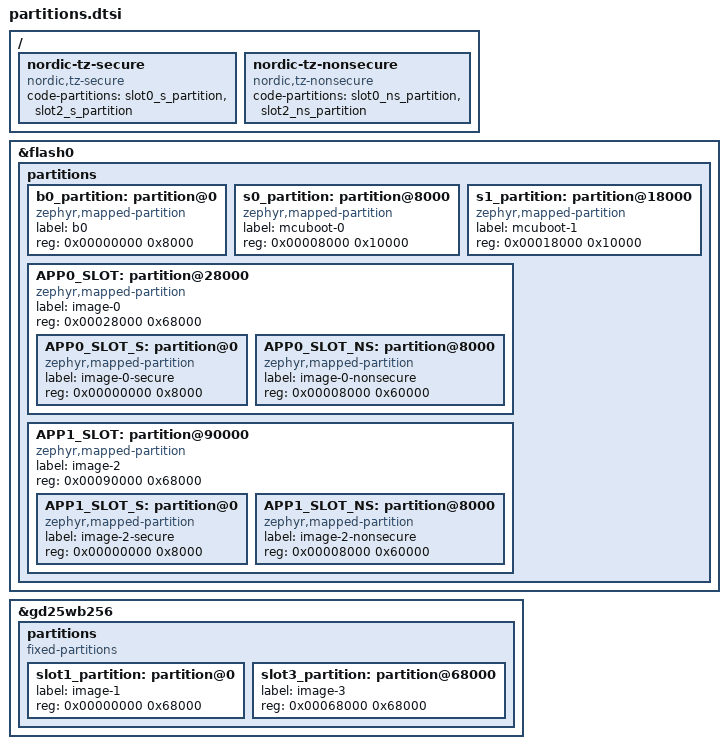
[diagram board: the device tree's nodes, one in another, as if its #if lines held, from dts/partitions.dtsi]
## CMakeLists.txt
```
cmake_minimum_required(VERSION 3.20.0)

find_package(Zephyr REQUIRED HINTS $ENV{ZEPHYR_BASE})
project(app0)

target_include_directories(app PRIVATE common)
target_sources(app PRIVATE src/main.c common/update.c)
```

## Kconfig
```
rsource "common/Kconfig"
source "Kconfig.zephyr"
```

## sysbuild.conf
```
# Two stage bootloader (b0 + MCUboot)
SB_CONFIG_SECURE_BOOT_APPCORE=y
SB_CONFIG_BOOTLOADER_MCUBOOT=y

SB_CONFIG_MCUBOOT_MODE_SWAP_USING_MOVE=y

# app0 = image 0, app1 = image 1
# MCUboot adds its own s0/s1 pair as image 2
SB_CONFIG_MCUBOOT_UPDATEABLE_IMAGES=2
```

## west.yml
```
manifest:
  remotes:
    - name: savosaicic
      url-base: https://github.com/savosaicic

  projects:
    - name: nrf
      repo-path: sdk-nrf
      remote: savosaicic
      revision: c24ab47cc679d7ebbf858c0a5f1238c8fe9de8c6
      import: true

  self:
    path: nrf-two-app
```

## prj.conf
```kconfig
CONFIG_LOG=y
CONFIG_REBOOT=y
CONFIG_DK_LIBRARY=y
CONFIG_TFM_PROFILE_TYPE_MINIMAL=y

CONFIG_MAIN_STACK_SIZE=4096
CONFIG_HEAP_MEM_POOL_SIZE=4096

# LTE
CONFIG_NRF_MODEM_LIB=y
CONFIG_LTE_LINK_CONTROL=y
CONFIG_NETWORKING=y
CONFIG_NET_SOCKETS=y
CONFIG_NET_NATIVE=n

# FOTA
CONFIG_FOTA_DOWNLOAD=y
CONFIG_DOWNLOADER=y
CONFIG_DOWNLOADER_STACK_SIZE=4096
CONFIG_DFU_TARGET=y
CONFIG_DFU_TARGET_MCUBOOT=y
CONFIG_IMG_MANAGER=y
CONFIG_STREAM_FLASH=y
CONFIG_IMG_ERASE_PROGRESSIVELY=y
CONFIG_FLASH=y
CONFIG_FLASH_MAP=y

# Secondary slots on external flash
CONFIG_SPI=y
CONFIG_SPI_NOR=y
CONFIG_SPI_NOR_SFDP_DEVICETREE=y
CONFIG_SPI_NOR_FLASH_LAYOUT_PAGE_SIZE=4096
```

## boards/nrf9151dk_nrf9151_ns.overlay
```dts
#include "../dts/partitions.dtsi"
#include <samples/cellular/nrf91_sram_partitions.dtsi>
```

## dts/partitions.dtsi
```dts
/*
 * Two application flash layout for the nRF9151DK
 *
 * MCUboot image pair 0 = app0 (primary slot0, secondary slot1)
 * MCUboot image pair 1 = app1 (primary slot2, secondary slot3)
 * MCUboot image pair 2 = MCUboot s0/s1 self-update
 *
 *   0x0000_0000  b0 (NSIB)                     ( 32 kB)
 *   0x0000_8000  s0: MCUboot slot A            ( 64 kB)
 *   0x0001_8000  s1: MCUboot slot B            ( 64 kB)
 *   0x0002_8000  app0 primary                  (416 kB)
 *     0x0002_8000  TF-M (secure)               ( 32 kB)
 *     0x0003_0000  app0 (non-secure)           (384 kB)
 *   0x0009_0000  app1 primary                  (416 kB)
 *     0x0009_0000  TF-M (secure)               ( 32 kB)
 *     0x0009_8000  app1 (non-secure)           (384 kB)
 *   0x000f_8000  free                          ( 32 kB)
 *
 *   ext 0x0000_0000  app0 secondary (slot1)    (416 kB)
 *   ext 0x0006_8000  app1 secondary (slot3)    (416 kB)
 *
 * TF-M and imgtool resolve slot0_* from the image's own devicetree, so app1
 * includes this file with APP1_VIEW defined: same layout but the slot0_*
 * labels sit on app1's slot and slot2_* on app0's. The secondary labels
 * (slot1/slot3) are MCUboot global in both views, so fota_download with
 * img_num N always writes slot<2N+1>.
 */

#ifdef APP1_VIEW
#define APP0_SLOT    slot2_partition
#define APP0_SLOT_S  slot2_s_partition
#define APP0_SLOT_NS slot2_ns_partition
#define APP1_SLOT    slot0_partition
#define APP1_SLOT_S  slot0_s_partition
#define APP1_SLOT_NS slot0_ns_partition
#else
#define APP0_SLOT    slot0_partition
#define APP0_SLOT_S  slot0_s_partition
#define APP0_SLOT_NS slot0_ns_partition
#define APP1_SLOT    slot2_partition
#define APP1_SLOT_S  slot2_s_partition
#define APP1_SLOT_NS slot2_ns_partition
#endif

/delete-node/ &boot_partition;
/delete-node/ &slot0_partition;
/delete-node/ &slot1_partition;
/delete-node/ &tfm_ps_partition;
/delete-node/ &tfm_its_partition;
/delete-node/ &tfm_otp_partition;
/delete-node/ &storage_partition;

&flash0 {
	partitions {
		b0_partition: partition@0 {
			compatible = "zephyr,mapped-partition";
			label = "b0";
			reg = <0x00000000 0x8000>;
		};

		s0_partition: partition@8000 {
			compatible = "zephyr,mapped-partition";
			label = "mcuboot-0";
			reg = <0x00008000 0x10000>;
		};

		s1_partition: partition@18000 {
			compatible = "zephyr,mapped-partition";
			label = "mcuboot-1";
			reg = <0x00018000 0x10000>;
		};

		APP0_SLOT: partition@28000 {
			compatible = "zephyr,mapped-partition";
			label = "image-0";
			reg = <0x00028000 0x68000>;
			ranges = <0x0 0x00028000 0x68000>;
			#address-cells = <1>;
			#size-cells = <1>;

			APP0_SLOT_S: partition@0 {
				compatible = "zephyr,mapped-partition";
				label = "image-0-secure";
				reg = <0x00000000 0x8000>;
			};

			APP0_SLOT_NS: partition@8000 {
				compatible = "zephyr,mapped-partition";
				label = "image-0-nonsecure";
				reg = <0x00008000 0x60000>;
			};
		};

		APP1_SLOT: partition@90000 {
			compatible = "zephyr,mapped-partition";
			label = "image-2";
			reg = <0x00090000 0x68000>;
			ranges = <0x0 0x00090000 0x68000>;
			#address-cells = <1>;
			#size-cells = <1>;

			APP1_SLOT_S: partition@0 {
				compatible = "zephyr,mapped-partition";
				label = "image-2-secure";
				reg = <0x00000000 0x8000>;
			};

			APP1_SLOT_NS: partition@8000 {
				compatible = "zephyr,mapped-partition";
				label = "image-2-nonsecure";
				reg = <0x00008000 0x60000>;
			};
		};
	};
};

&gd25wb256 {
	status = "okay";

	partitions {
		compatible = "fixed-partitions";
		#address-cells = <1>;
		#size-cells = <1>;

		slot1_partition: partition@0 {
			label = "image-1";
			reg = <0x00000000 0x68000>;
		};

		slot3_partition: partition@68000 {
			label = "image-3";
			reg = <0x00068000 0x68000>;
		};
	};
};

/ {
	/delete-node/ nordic-tz-secure;
	/delete-node/ nordic-tz-nonsecure;

	nordic-tz-secure {
		compatible = "nordic,tz-secure";
		code-partitions = <&slot0_s_partition>, <&slot2_s_partition>;
	};

	nordic-tz-nonsecure {
		compatible = "nordic,tz-nonsecure";
		code-partitions = <&slot0_ns_partition>, <&slot2_ns_partition>;
	};
};
```

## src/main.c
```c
#include <zephyr/logging/log.h>

#include "update.h"

LOG_MODULE_REGISTER(app0);

int main(void)
{
	LOG_INF("*** APP0 ***");
	update_run();
	return 0;
}
```
